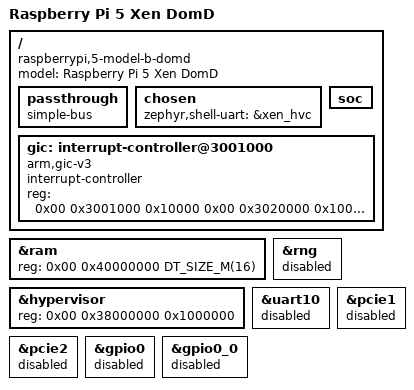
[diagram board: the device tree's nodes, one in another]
/*
 * Copyright (C) 2024 EPAM Systems.
 *
 * SPDX-License-Identifier: Apache-2.0
 */

#include <mem.h>
#include <zephyr/dt-bindings/gpio/gpio.h>

/delete-node/ &gic;
/delete-node/ &sram0;

/ {
	compatible = "raspberrypi,5-model-b-domd", "raspberrypi,5-model-b", "brcm,bcm2712";
	model = "Raspberry Pi 5 Xen DomD";
	#size-cells = <1>;

	passthrough {
		compatible = "simple-bus";
		ranges;
		#address-cells = <2>;
		#size-cells = <1>;
	};

	chosen {
		zephyr,shell-uart = &xen_hvc;
		/delete-property/ zephyr,pcie-controller;
		/delete-property/ zephyr,entropy;
	};

	soc {
		#address-cells = <2>;
		#size-cells = <1>;
	};

	gic: interrupt-controller@3001000 {
		compatible = "arm,gic-v3", "arm,gic";
		#interrupt-cells = <4>;
		#address-cells = <0>;
		interrupt-controller;
		reg = <0x00 0x3001000 0x10000 0x00 0x3020000 0x1000000>;
	};
};

&ram {
	reg = <0x00 0x40000000 DT_SIZE_M(16)>;
};

&hypervisor {
	reg = <0x00 0x38000000 0x1000000>;
};

&rng {
	status = "disabled";
};

&uart10 {
	status = "disabled";
};

&pcie1 {
	status = "disabled";
};

&pcie2 {
	status = "disabled";
};

&gpio0 {
	status = "disabled";
};

&gpio0_0 {
	status = "disabled";
};
